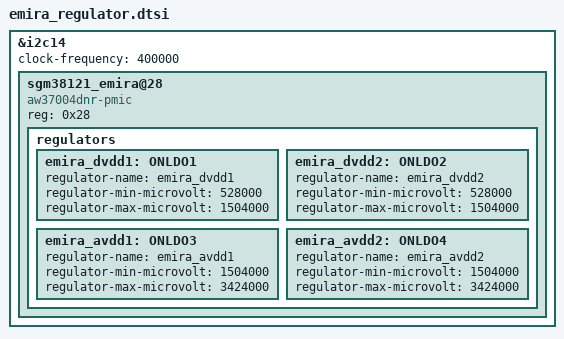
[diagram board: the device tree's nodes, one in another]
// SPDX-License-Identifier: GPL-2.0
/*
 * Copyright (C) 2021 MediaTek Inc.
 */

// &pio {
// 	wl28681c_konka_default: state_default_a2 {
// 		pins_cmd_dat {
// 			pinmux = <PINMUX_GPIO212__FUNC_GPIO212>;
// 		};
// 	};
// 	// GPIO90 pull up to enable dvdd supply
// 	wl28681c_konka_reset_high: state_reset_high_a2 {
// 		pins_cmd_dat {
// 			pinmux = <PINMUX_GPIO212__FUNC_GPIO212>,
// 			<PINMUX_GPIO180__FUNC_GPIO180>;
// 			slew-rate = <1>;
// 			output-high;
// 		};
// 	};
// 	wl28681c_konka_reset_low: state_reset_low_a2 {
// 		pins_cmd_dat {
// 			pinmux = <PINMUX_GPIO212__FUNC_GPIO212>;
// 			slew-rate = <1>;
// 			output-low;
// 		};
// 	};
// };

&i2c14 {
	clock-frequency = <400000>;

	sgm38121_emira@28{
		compatible = "aw37004dnr-pmic";
		reg = <0x28>;
		regulators {
			emira_dvdd1:ONLDO1 {
				regulator-name = "emira_dvdd1";
				regulator-min-microvolt = <528000>;
				regulator-max-microvolt = <1504000>;
			};
			emira_dvdd2:ONLDO2 {
				regulator-name = "emira_dvdd2";
				regulator-min-microvolt = <528000>;
				regulator-max-microvolt = <1504000>;
			};
			emira_avdd1:ONLDO3 {
				regulator-name = "emira_avdd1";
				regulator-min-microvolt = <1504000>;
				regulator-max-microvolt = <3424000>;
			};
			emira_avdd2:ONLDO4 {
				regulator-name = "emira_avdd2";
				regulator-min-microvolt = <1504000>;
				regulator-max-microvolt = <3424000>;
			};
		};
	};

	// aw37004_emira@31 {
	// 	compatible = "aw37004dnr-pmic";
	// 	reg = <0x31>;
	// 	regulators {
	// 		aw37004dnr_dvdd1:ONLDO1 {
	// 			regulator-name = "aw37004dnr_dvdd1";
	// 			regulator-min-microvolt = <600000>;
	// 			regulator-max-microvolt = <1800000>;
	// 		};
	// 		aw37004dnr_dvdd2:ONLDO2 {
	// 			regulator-name = "aw37004dnr_dvdd2";
	// 			regulator-min-microvolt = <600000>;
	// 			regulator-max-microvolt = <1800000>;
	// 		};
	// 		aw37004dnr_avdd1:ONLDO3 {
	// 			regulator-name = "aw37004dnr_avdd1";
	// 			regulator-min-microvolt = <1200000>;
	// 			regulator-max-microvolt = <4300000>;
	// 		};
	// 		aw37004dnr_avdd2:ONLDO4 {
	// 			regulator-name = "aw37004dnr_avdd2";
	// 			regulator-min-microvolt = <1200000>;
	// 			regulator-max-microvolt = <4300000>;
	// 		};
	// 	};
	// };
};



